# A64 register map
Vendor: Allwinner; Series: A64; File version: 0.1
CPU: CA53 0, little endian, MPU, no FPU, 0 interrupt priority bits
Registers are 32-bit, read-write, reset 0x0 unless marked. A register's access mark holds for its fields unless they carry their own. Offsets are from the block's base; [hi:lo] are bit positions; lines under a group give offsets from that group; {n}, {i} and the like mark numbered series.

## EMAC
Base 0x01C30000
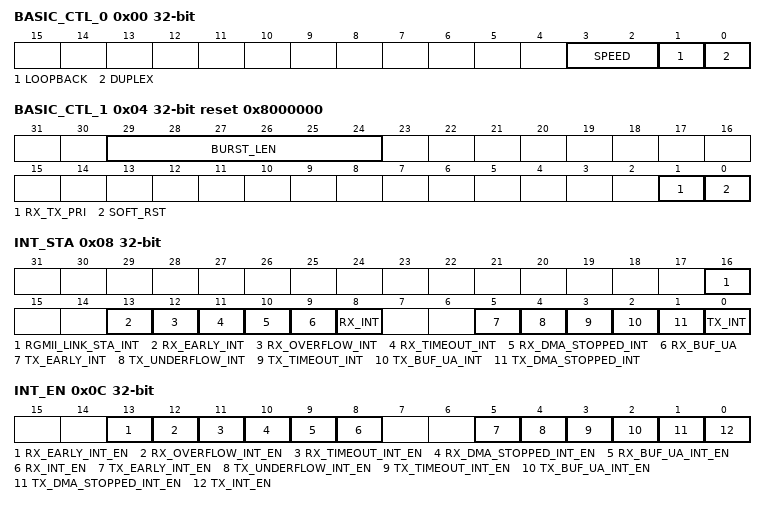
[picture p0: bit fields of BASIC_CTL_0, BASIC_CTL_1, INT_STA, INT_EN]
0x00 BASIC_CTL_0 — Basic Control 0 Register
  [3:2] SPEED — 00: 1000Mbps 11: 100Mbps 10: 10Mbps 01: Reserved
    0=_1000Mbps; 3=_100Mbps; 2=_10Mbps
  [1] LOOPBACK — 0: Disable; 1: Enable;
    0=Disable; 1=Enable
  [0] DUPLEX — 0: Half-duplex 1: Full-duplex
    0=half_duplex; 1=full_duplex
0x04 BASIC_CTL_1 reset 0x8000000 — Basic Control 1 Register
  [29:24] BURST_LEN — The burst length of RX and TX DMA transfer.
  [1] RX_TX_PRI — 0: RX DMA and TX DMA have same priority 1: RX DMA has priority over TX DMA
    0=RX DMA and TX DMA have same priority; 1=RX_DMA (RX DMA has priority over TX DMA)
  [0] SOFT_RST — When this bit is set, soft reset all registers and logic. All clock inputs must be valid before soft rest. This bit is cleared internally when the reset operation is completed fully. Before write any register, this bit should read a 0.
0x08 INT_STA — Interrupt Status Register
  [16] RGMII_LINK_STA_INT ro — When this bit is asserted, the link status of RGMII interface is changed.
  [13] RX_EARLY_INT ro — When this bit asserted, the RX DMA had filled the first data buffer of the receive frame.
  [12] RX_OVERFLOW_INT ro — When this bit is asserted, the RX FIFO had an overflow error.
  [11] RX_TIMEOUT_INT ro — When this bit asserted, the length of receive frame is greater than 2048 bytes(10240 when JUMBO_FRM_EN is set)
  [10] RX_DMA_STOPPED_INT ro — When this bit asserted, the RX DMA FSM is stopped.
  [9] RX_BUF_UA ro — _INT When this asserted, the RX DMA can`t acquire next RX descriptor and RX DMA FSM is suspended. The ownership of next RX descriptor should be changed to RX DMA. The RX DMA FSM will resume when write to DMA_RX_START bit or next receive frame is coming.
  [8] RX_INT ro — When this bit is asserted, a frame reception is completed. The RX DMA FSM remains in the running state.
  [5] TX_EARLY_INT ro — When this bit is asserted , the frame is transmitted to FIFO totally.
  [4] TX_UNDERFLOW_INT ro — When this bit is asserted, the TX FIFO had an underflow error.
  [3] TX_TIMEOUT_INT ro — When this bit is asserted, the transmitter had been excessively active.
  [2] TX_BUF_UA_INT ro — When this asserted, the TX DMA can not acquire next TX descriptor and TX DMA FSM is suspended. The ownership of next TX descriptor should be changed to TX DMA. The TX DMA FSM will resume when write to DMA_TX_START bit.
  [1] TX_DMA_STOPPED_INT ro — When this bit is asserted, the TX DMA FSM is stopped.
  [0] TX_INT ro — When this bit is asserted, a frame transmission is completed.
0x0C INT_EN — Interrupt Enable Register
  [13] RX_EARLY_INT_EN — 0: Disable early receive interrupt enable 1: Enable early receive interrupt enable
    0=Disable early receive interrupt enable; 1=Enable early receive interrupt enable
  [12] RX_OVERFLOW_INT_EN — 0: Disable overflow interrupt 1: Enable overflow interrupt
    0=Disable overflow interrupt; 1=Enable overflow interrupt
  [11] RX_TIMEOUT_INT_EN — 0: Disable receive timeout interrupt 1: Enable receive timeout interrupt
    0=Disable receive timeout interrupt; 1=Enable receive timeout interrupt
  [10] RX_DMA_STOPPED_INT_EN — 0: Disable receive DMA FSM stopped interrupt 1: Enable receive DMA FSM stopped interrupt
    0=Disable receive DMA FSM stopped interrupt; 1=Enable receive DMA FSM stopped interrupt
  [9] RX_BUF_UA_INT_EN — 0: Disable receive buffer unavailable interrupt 1: Enable receive buffer unavailable interrupt
    0=Disable receive buffer unavailable interrupt; 1=Enable receive buffer unavailable interrupt
  [8] RX_INT_EN — 0: Disable receive interrupt 1: Enable receive interrupt
    0=Disable receive interrupt; 1=Enable receive interrupt
  [5] TX_EARLY_INT_EN — 0: Disable early transmit interrupt 1: Enable early transmit interrupt
    0=Disable early transmit interrupt; 1=Enable early transmit interrupt
  [4] TX_UNDERFLOW_INT_EN — 0: Disable underflow interrupt 1: Enable underflow interrupt
    0=Disable underflow interrupt; 1=Enable underflow interrupt
  [3] TX_TIMEOUT_INT_EN — 0: Disable transmit timeout interrupt 1: Enable transmit timeout interrupt
    0=Disable transmit timeout interrupt; 1=Enable transmit timeout interrupt
  [2] TX_BUF_UA_INT_EN — 0: Disable transmit buffer available interrupt 1: Enable transmit buffer available interrupt
    0=Disable transmit buffer available interrupt; 1=Enable transmit buffer available interrupt
  [1] TX_DMA_STOPPED_INT_EN — 0: Disable transmit DMA FSM stopped interrupt 1: Enable transmit DMA FSM stopped interrupt
    0=Disable transmit DMA FSM stopped interrupt; 1=Enable transmit DMA FSM stopped interrupt
  [0] TX_INT_EN — 0: Disable transmit interrupt 1: Enable transmit interrupt
    0=Disable transmit interrupt; 1=Enable transmit interrupt
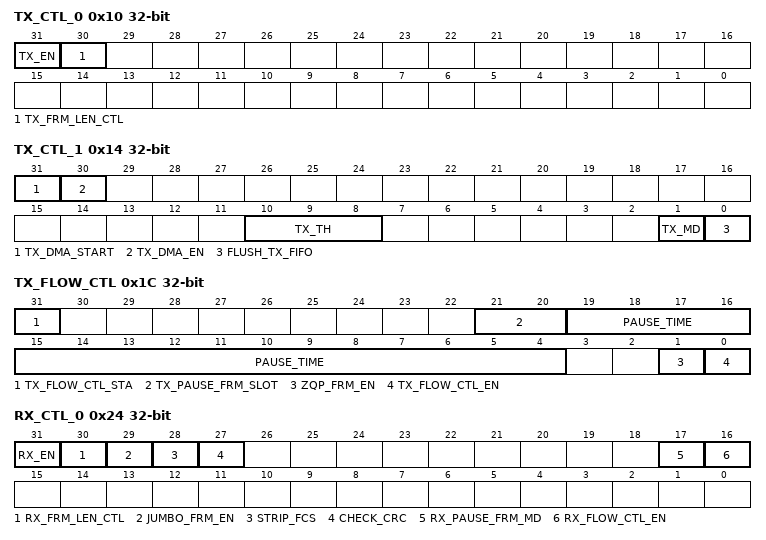
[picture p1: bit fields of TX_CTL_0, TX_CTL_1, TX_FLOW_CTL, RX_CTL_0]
0x10 TX_CTL_0 — Transmit Control 0 Register
  [31] TX_EN — Enable transmitter. 0: Disable transmitter after current transmission 1: Enable
    0=Disable transmitter after current transmission; 1=Enable
  [30] TX_FRM_LEN_CTL — 0: Allow to transmit frames no more than 2,048 bytes (10,240 if JUMBO_FRM_EN is set) and cut off any bytes after that 1:Allow to transmit frames of up to 16,384 bytes
    0=Allow to transmit frames no more than 2,048 bytes (10,240 if JUMBO_FRM_EN is set) and cut off any bytes after that 1:Allow to transmit frames of up to 16,384 bytes
0x14 TX_CTL_1 — Transmit Control 1 Register
  [31] TX_DMA_START — When set this bit, the TX DMA FSM will go no to work. It is cleared internally and always read a 0.
  [30] TX_DMA_EN — 0: Stop TX DMA after the completion of current frame transmission. 1: Start and run TX DMA.
    0=Stop TX DMA after the completion of current frame transmission; 1=Start and run TX DMA
  [10:8] TX_TH — The threshold value of TX DMA FIFO. When TX_MD is 0, transmission starts when the size of frame in TX DMA FIFO is greater than the threshold. In addition, full frames with a length less than the threshold are transferred automatically. 000: 64 001: 128 010: 192 011: 256 Others: Reserved
    0=_64; 1=_128; 2=_192; 3=_256
  [1] TX_MD — 0: Transmission starts after the number of data in TX DAM FIFO is greater than TX_TH 1: Transmission starts after a full frame located in TX DMA FIFO
    0=Transmission starts after the number of data in TX DAM FIFO is greater than TX_TH; 1=Transmission starts after a full frame located in TX DMA FIFO
  [0] FLUSH_TX_FIFO — The functionality that flush the data in the TX FIFO. 0: Enable 1: Disable
    0=Enable; 1=Disable
0x1C TX_FLOW_CTL — Transmit Flow Control Register
  [31] TX_FLOW_CTL_STA — This bit indicates a pause frame transmission is in progress. When the configuration of flow control is ready, set this bit to transmit a pause frame in full-duplex mode or activate the backpressure function. After completion of transmission, this bit will be cleared automatically. Before write register TX_FLOW_CTRL, this bit must be read as 0.
  [21:20] TX_PAUSE_FRM_SLOT — The threshold of the pause timer at which the input flow control signal is checked for automatic retransmission of pause frame. The threshold values should be always less than the PAUSE_TIME
  [19:4] PAUSE_TIME — The pause time field in the transmitted control frame.
  [1] ZQP_FRM_EN — When set, enable the functionality to generate Zero-Quanta Pause control frame.
  [0] TX_FLOW_CTL_EN — When set, enable flow control operation to transmit pause frames in full-duplex mode, or enable the back-pressure operation in half-duplex mode. 0: Disable 1: Enable
    0=Disable; 1=Enable
0x20 TX_DMA_LIST
  [31:0] TX_DESC_LIST — The base address of transmi t descriptor list. It must be 32-bit aligned.
0x24 RX_CTL_0 — Receive Control 0 Register
  [31] RX_EN — Enable receiver 0: Disable receiver after current reception 1: Enable
    0=Disable receiver after current reception; 1=Enable
  [30] RX_FRM_LEN_CTL — 0: Allow to receive frames less than or equal to 2,048 bytes (10,240 if JUMBO_FRM_EN is set) and cuts off any bytes received after that 1: Allow to receive frames of up to 16,384 bytes
    0=Allow to receive frames less than or equal to 2,048 bytes (10,240 if JUMBO_FRM_EN is set) and cuts off any bytes received after that; 1=Allow to receive frames of up to 16,384 bytes
  [29] JUMBO_FRM_EN — When set, allows Jumbo frames of 9,018 bytes without reporting a giant frame error in the receive frame status.
  [28] STRIP_FCS — When set, strip the Pad/FCS field on received frames only when the length`s field value is less than or equal to 1,500 bytes.
  [27] CHECK_CRC — When set, calculate CRC and check the IPv4 Header Checksum.
  [17] RX_PAUSE_FRM_MD — 0: Only detect multicast pause frame specified in the 802.3x standard. 1: In addition to detect multicast pause frame specified in the 802.3x standard, also detect unicast pause frame with address specified in MAC Address 0 High Register and MAC address 0 Low Register.
    0=Only detect multicast pause frame specified in the 802.3x standard; 1=In (In addition to detect multicast pause frame specified in the 802.3x standard, also detect unicast pause frame with address specified in MAC Address 0 High Register and MAC address 0 Low Register.)
  [16] RX_FLOW_CTL_EN — When set, enable the functionality that decode the received pause frame and disable its transmitter for a specified time by pause frame.
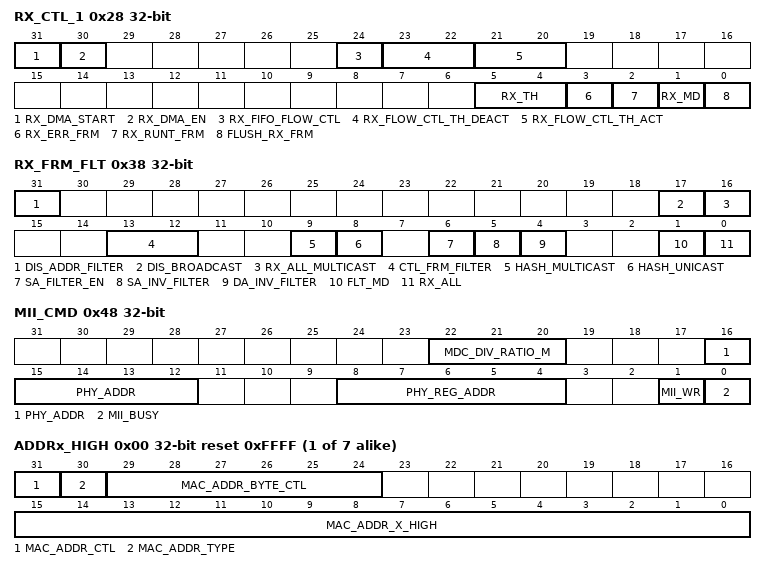
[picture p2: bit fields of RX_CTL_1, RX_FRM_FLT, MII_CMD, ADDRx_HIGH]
0x28 RX_CTL_1 — Receive Control 1 Register
  [31] RX_DMA_START — When set, the RX DMA will go no to work. It is cleared internally and always read a 0.
  [30] RX_DMA_EN — 0: Stop RX DMA after finish receiving current frame 1: Start and run RX DMA
    0=Stop RX DMA after finish receiving current frame; 1=Start and run RX DMA
  [24] RX_FIFO_FLOW_CTL — 0: Disable RX flow control 1: Enable RX flow control based on RX_FLOW_CTL_TH_DEACT and RX_FLOW_CTL_TH_ACT
    0=Disable RX flow control; 1=Enable RX flow control based on RX_FLOW_CTL_TH_DEACT and RX_FLOW_CTL_TH_ACT
  [23:22] RX_FLOW_CTL_TH_DEACT — The threshold for deactivating flow control in both half-duplex mode and full-duplex mode 00: Full minus 1 KB 01: Full minus 2 KB 10: Full minus 3 KB 11: Full minus 4 KB
    {v}=Full minus {v+1} KB (v=0..3)
  [21:20] RX_FLOW_CTL_TH_ACT — The threshold for activating flow control in both half-duplex mode and full-duplex mode. 00: Full minus 1 KB 01: Full minus 2 KB 10: Full minus 3 KB 11: Full minus 4 KB
    {v}=Full minus {v+1} KB (v=0..3)
  [5:4] RX_TH — The threshold value of RX DMA FIFO. When RX_MD is 0, RX DMA starts to transfer data when the size of received frame in RX DMA FIFO is greater than the threshold. In addition, full frames with a length less than the threshold are transferred automatically. 00: 64 01: 32 10: 96 11: 128
    0=_64; 1=_32; 2=_96; 3=_128
  [3] RX_ERR_FRM — 0: RX DMA drops frames with error 1: RX DMA forwards frames with error
    0=RX DMA drops frames with error; 1=RX DMA forwards frames with error
  [2] RX_RUNT_FRM — When set, forward undersized frames with no error and length less than 64bytes
  [1] RX_MD — 0: RX DMA reads data from RX DMA FIFO to host memory after the number of data in RX DAM FIFO is greater than RX_TH 1: RX DMA reads data from RX DMA FIFO to host memory after a complete frame has been written to RX DMA FIFO
    0=RX DMA reads data from RX DMA FIFO to host memory after the number of data in RX DAM FIFO is greater than RX_TH; 1=RX DMA reads data from RX DMA FIFO to host memory after a complete frame has been written to RX DMA FIFO
  [0] FLUSH_RX_FRM — The functionality that flush the frames when receive descriptors/buffers is unavailable 0: Enable 1: Disable
    0=Enable; 1=Disable
0x34 RX_DMA_LIST
  [31:0] RX_DESC_LIST — The base address of receive descriptor list. It must be 3 2-bit aligned.
0x38 RX_FRM_FLT — Receive Frame Filter Register
  [31] DIS_ADDR_FILTER — 0: Enable address filter 1: Disable address filter
    0=Enable address filter; 1=Disable address filter
  [17] DIS_BROADCAST — 0: Receive all broadcast frames 1: Drop all broadcast frames
    0=Receive all broadcast frames; 1=Drop all broadcast frames
  [16] RX_ALL_MULTICAST — 0: Filter multicast frame according to HASH_MULTICAST 1: Receive all multicast frames
    0=Filter multicast frame according to HASH_MULTICAST; 1=Receive all multicast frames
  [13:12] CTL_FRM_FILTER — 00, 01: Drop all control frames 10: Receive all control frames 11: Receive all control frames when pass the address filter
  [9] HASH_MULTICAST — 0: Filter multicast frames by comparing the DA field with the values in DA MAC address registers 1: Filter multicast frames according to the hash table
    0=Filter multicast frames by comparing the DA field with the values in DA MAC address registers; 1=Filter multicast frames according to the hash table
  [8] HASH_UNICAST — 0: Filter unicast frames by comparing the DA field with the values in DA MAC address registers 1: Filter unicast frames according to the hash table
    0=Filter unicast frames by comparing the DA field with the values in DA MAC address registers; 1=Filter unicast frames according to the hash table
  [6] SA_FILTER_EN — 0: Receive frames and update the result of SA filter 1: Update the result of SA filter. In addition, if the SA field of received frame does not match the values in SA MAC address registers, drop this frame.
    0=Receive frames and update the result of SA filter; 1=Update the result of SA filter. In addition, if the SA field of received frame does not match the values in SA MAC address registers, drop this frame.
  [5] SA_INV_FILTER — 0: When the SA field of current frame matches the values in SA MAC address registers, it passes the SA filter 1: When the SA filed of current frame does not match the values in SA MAC address registers,, it passes the SA filter
    0=When the SA field of current frame matches the values in SA MAC address registers, it passes the SA filter; 1=When the SA filed of current frame does not match the values in SA MAC address registers,, it passes the SA filter
  [4] DA_INV_FILTER — 0: Normal filtering of frames is performed 1: Filter both unicast and multicast frames by comparing DA field in inverse filtering mode
    0=Normal filtering of frames is performed; 1=Filter both unicast and multicast frames by comparing DA field in inverse filtering mode
  [1] FLT_MD — 0: If the HASH_MULTICAST or HASH_UNICAST is set, the frame is passed only when it matches the Hash filter 1: Receive the frame when it pass the address register filter or the hash filter(set by HASH_MULTICAST or HASH_UNICAST)
    0=If (If the HASH_MULTICAST or HASH_UNICAST is set, the frame is passed only when it matches the Hash filter); 1=Receive the frame when it pass the address register filter or the hash filter(set by HASH_MULTICAST or HASH_UNICAST)
  [0] RX_ALL — 0: Receive the frames that pass the SA/DA address filter 1: Receive all frames and update the result of address filter(pass or fail) in the receive status word
    0=Receive the frames that pass the SA/DA address filter; 1=Receive all frames and update the result of address filter(pass or fail) in the receive status word
0x40 RX_HASH_0 — Hash Table 0 Register
  [31:0] HASH_TAB_0 — The upper 32 bits of Hash t able for receive frame filter.
0x44 RX_HASH_1 — Hash Table 1 Register
  [31:0] HASH_TAB_1 — The lower 32 bits of Hash table for receive frame filter.
0x48 MII_CMD — Management Interface Command Register
  [22:20] MDC_DIV_RATIO_M — MDC clock divide ration(m). The source of MDC clock is AHB clock. 000: 16 001: 32 010: 64 011: 128 Others: Reserved
    0=_16; 1=_32; 2=_64; 3=128 Others: Reserved
  [16:12] PHY_ADDR — Select a PHY device from 32 possible candidates.
  [8:4] PHY_REG_ADDR — Select register in the selected PHY device
  [1] MII_WR — 0: Read register in selected PHY and return data in EMAC_GMII_DATA 1: Write register in selected PHY using data in EMAC_GMII_DATA
    0=Read register in selected PHY and return data in EMAC_GMII_DATA; 1=Write register in selected PHY using data in EMAC_GMII_DATA
  [0] MII_BUSY — This bit indicates that a read or write operation is in progress. When prepared the data and register address for a write operation or the register address for a read operation, set this bit and start to access register in PHY. When this bit is cleared automatically, the read or write operation is over and the data in EMAC_GMII_DATA is valid for a read operation.
0x4C MII_DATA — Management Interface Data Register
  [15:0] MII_DATA — The 16-bit data to be written to or read from the register in the selected PHY.
0x50 ADDR0_HIGH reset 0xFFFF
  [15:0] MAC_ADDR_0_HIGH — The upper 16bits of the 1 MAC address.
0x54 ADDR0_LOW reset 0xFFFFFFFF
  [31:0] MAC_ADDR_0_LOW — The lower 32bits of 1 MAC address.
{0x50+8i} _x_{i} (i=1..7) group
  0x00 ADDRx_HIGH reset 0xFFFF
    [31] MAC_ADDR_CTL — 0: MAC address x(x: 1~7) is not valid, and it will be ignored by the address filter 1: MAC address x(x 1~7) is valid
      0=MAC_address_x_openingparen_x_colon__1_tilde_7_closingparen_ (MAC address x(x: 1~7) is not valid, and it will be ignored by the address filter); 1=MAC_address_x_openingparen_x_1_tilde_7_closingparen_ (MAC address x(x 1~7) is valid)
    [30] MAC_ADDR_TYPE — 1: MAC address x(x:1~7) used to compare with the source address of the received frame 0: MAC address x(x:1~7) used to compare with the destination address of the received frame
      1=MAC_address_x_openingparen_x_colon_1_tilde_7_closingparen__used_to_compare_with_the_source (MAC address x(x:1~7) used to compare with the source address of the received frame); 0=MAC_address_x_openingparen_x_colon_1_tilde_7_closingparen__used_to_compare_with_the_destination (MAC address x(x:1~7) used to compare with the destination address of the received frame)
    [29:24] MAC_ADDR_BYTE_CTL — MAC address byte control mask. The lower bit of mask controls the lower byte of in MAC address x(x:1~7). When the bit of mask is 1, do not compare the corresponding byte.
    [15:0] MAC_ADDR_X_HIGH — The upper 16bits of the MAC address x(x:1~7).
  0x04 ADDRx_LOW reset 0xFFFFFFFF
    [31:0] MAC_ADDR_X_LOW — The lower 32bits of MAC address x(x:1~7).
0xB0 TX_DMA_STA — Transmit DMA Status Register
  [2:0] TX_DMA_STA ro — The state of Transmit DMA FSM. 000: STOP: When reset or disable TX DMA; 001: RUN_FETCH_DESC: Fetching TX DMA descriptor; 010: RUN_WAIT_STA: Waiting for the status of TX frame; 011: RUN_TRANS_DATA: Passing frame from host memory to TX DMA FIFO; 111: RUN_CLOSE_DESC: Closing TX descriptor. 110: SUSPEND: TX descriptor unavailable or TX DMA FIFO underflow; 100, 101: Reserved;
    0=STOP (STOP: When reset or disable TX DMA;); 1=RUN_FETCH_DESC (RUN_FETCH_DESC: Fetching TX DMA descriptor;); 2=RUN_WAIT_STA (RUN_WAIT_STA: Waiting for the status of TX frame;); 3=RUN_TRANS_DATA (RUN_TRANS_DATA: Passing frame from host memory to TX DMA FIFO;); 7=RUN_CLOSE_DESC (RUN_CLOSE_DESC: Closing TX descriptor.); 6=SUSPEND (SUSPEND: TX descriptor unavailable or TX DMA FIFO underflow; 100, 101: Reserved;)
0xB4 TX_DMA_CUR_DESC
  [31:0] CURRENT_TRANSMIT ro — The address of current transmit descriptor.
0xB8 TX_DMA_CUR_BUF
  [31:0] CURRENT_TRANSMIT ro — The address of current transmit DMA buffer.
0xC0 RX_DMA_STA — Receive DMA Status Register
  [2:0] RX_DMA_STA ro — The state of RX DMA FSM. 000: STOP: When reset or disable RX DMA;. 001: RUN_FETCH_DESC: Fetching RX DMA descriptor; 011: RUN_WAIT_FRM: Waiting for frame. 100: SUSPEND: RX descriptor unavailable; 101: RUN_CLOSE_DESC: Closing RX descriptor. 111: RUN_TRANS_DATA: Passing frame from host memory to RX DMA FIFO; 010, 110: Reserved.
    0=STOP (STOP: When reset or disable RX DMA;.); 1=RUN_FETCH_DESC (RUN_FETCH_DESC: Fetching RX DMA descriptor;); 3=RUN_WAIT_FRM (RUN_WAIT_FRM: Waiting for frame.); 4=SUSPEND (SUSPEND: RX descriptor unavailable;); 5=RUN_CLOSE_DESC (RUN_CLOSE_DESC: Closing RX descriptor.); 7=RUN_TRANS_DATA (RUN_TRANS_DATA: Passing frame from host memory to RX DMA FIFO; 010, 110: Reserved.)
0xC4 RX_DMA_CUR_DESC
  [31:0] CURRENT_RECEIVE ro — The address of current receive descriptor
0xC8 RX_DMA_CUR_BUF
  [31:0] CURRENT_RECEIVE ro — The address of current receive DMA buffer
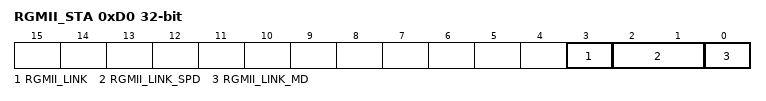
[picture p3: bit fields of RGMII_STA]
0xD0 RGMII_STA — RGMII Status Register
  [3] RGMII_LINK ro — The link status of RGMII interface 0: down 1: up
    0=down; 1=up
  [2:1] RGMII_LINK_SPD ro — The link speed of RGMII interface 00: 2.5 MHz 01: 25 MHz 10: 125 MHz
    0=_2_point_5 (2.5 MHz); 1=25 MHz; 2=125 MHz
  [0] RGMII_LINK_MD ro — The link Mode of RGMII interface 0: Half-Duplex 1: Full-Duplex
    0=half_Duplex; 1=full_Duplex
